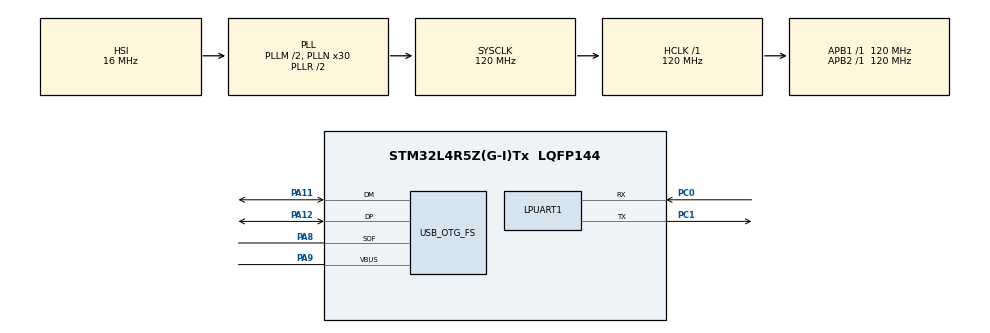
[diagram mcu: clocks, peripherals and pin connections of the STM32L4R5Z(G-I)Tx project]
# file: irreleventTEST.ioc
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LPUART1.WordLength=UART_WORDLENGTH_8B
Mcu.Family=STM32L4
Mcu.Name=STM32L4R5Z(G-I)Tx
Mcu.Package=LQFP144
NVIC.PriorityGroup=NVIC_PRIORITYGROUP_4
PA11.Mode=Device_Only
PA11.Signal=USB_OTG_FS_DM
PA12.Mode=Device_Only
PA12.Signal=USB_OTG_FS_DP
PA8.Mode=Activate_SOF_FS
PA8.Signal=USB_OTG_FS_SOF
PA9.Mode=Activate_VBUS
PA9.Signal=USB_OTG_FS_VBUS
PC0.Mode=Asynchronous
PC0.Signal=LPUART1_RX
PC1.Mode=Asynchronous
PC1.Signal=LPUART1_TX
ProjectManager.HeapSize=0x200
ProjectManager.StackSize=0x400
ProjectManager.TargetToolchain=STM32CubeIDE
RCC.ADCFreq_Value=96000000
RCC.AHBFreq_Value=120000000
RCC.APB1Freq_Value=120000000
RCC.APB1TimFreq_Value=120000000
RCC.APB2Freq_Value=120000000
RCC.APB2TimFreq_Value=120000000
RCC.CK48CLockSelection=RCC_USBCLKSOURCE_HSI48
RCC.CortexFreq_Value=120000000
RCC.HCLKFreq_Value=120000000
RCC.HSE_VALUE=8000000
RCC.HSI48_VALUE=48000000
RCC.HSI_VALUE=16000000
RCC.LSE_VALUE=32768
RCC.MSI_VALUE=4000000
RCC.PLLM1=2
RCC.PLLN=30
RCC.PLLSAI1N=12
RCC.PLLSourceVirtual=RCC_PLLSOURCE_HSI
RCC.SYSCLKFreq_VALUE=120000000
RCC.SYSCLKSource=RCC_SYSCLKSOURCE_PLLCLK
RCC.USBFreq_Value=48000000
RCC.VCOOutputFreq_Value=240000000
USB_OTG_FS.VirtualMode=Device_Only
board=custom

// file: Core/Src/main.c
/* USER CODE BEGIN Header */
/**
  ******************************************************************************
  * @file           : main.c
  * @brief          : Main program body
  ******************************************************************************
  * @attention
  *
  * Copyright (c) 2023 STMicroelectronics.
  * All rights reserved.
  *
  * This software is licensed under terms that can be found in the LICENSE file
  * in the root directory of this software component.
  * If no LICENSE file comes with this software, it is provided AS-IS.
  *
  ******************************************************************************
  */
/* USER CODE END Header */
#include "main.h"

UART_HandleTypeDef hlpuart1;

PCD_HandleTypeDef hpcd_USB_OTG_FS;

void SystemClock_Config(void);
static void MX_GPIO_Init(void);
static void MX_LPUART1_UART_Init(void);
static void MX_USB_OTG_FS_PCD_Init(void);

int main(void)
{

  /* MCU Configuration--------------------------------------------------------*/

  /* Reset of all peripherals, Initializes the Flash interface and the Systick. */
  HAL_Init();

  /* Configure the system clock */
  SystemClock_Config();

  /* Initialize all configured peripherals */
  MX_GPIO_Init();
  MX_LPUART1_UART_Init();
  MX_USB_OTG_FS_PCD_Init();
  /* USER CODE BEGIN 2 */
  char tt[50];
  char * msg = "start\n";
  HAL_UART_Transmit(&hlpuart1, (uint8_t*)msg, strlen(msg), HAL_MAX_DELAY);

  /* USER CODE END 2 */

  /* Infinite loop */
  /* USER CODE BEGIN WHILE */
  while (1)
  {

	  /**
	   * TEST PLAN:
	   * EMPTY CHAR ARRAY SIZE 50
	   * RECIEVE 1 CHAR
	   * USE TERMITE TO INPUT 10 CHAR
	   * TRANSMIT ARRAY
	   * SEE WHAT HAPPENS
	   */
	  HAL_UART_Receive(&hlpuart1, tt, 1, HAL_MAX_DELAY);
	  HAL_UART_Transmit(&hlpuart1, (uint8_t*)tt, strlen(tt), HAL_MAX_DELAY);

    /* USER CODE END WHILE */

  }
}

void SystemClock_Config(void)
{
  RCC_OscInitTypeDef RCC_OscInitStruct = {0};
  RCC_ClkInitTypeDef RCC_ClkInitStruct = {0};

  /** Configure the main internal regulator output voltage
  */
  if (HAL_PWREx_ControlVoltageScaling(PWR_REGULATOR_VOLTAGE_SCALE1_BOOST) != HAL_OK)
  {
    Error_Handler();
  }

  /** Initializes the RCC Oscillators according to the specified parameters
  * in the RCC_OscInitTypeDef structure.
  */
  RCC_OscInitStruct.OscillatorType = RCC_OSCILLATORTYPE_HSI48|RCC_OSCILLATORTYPE_HSI;
  RCC_OscInitStruct.HSIState = RCC_HSI_ON;
  RCC_OscInitStruct.HSI48State = RCC_HSI48_ON;
  RCC_OscInitStruct.HSICalibrationValue = RCC_HSICALIBRATION_DEFAULT;
  RCC_OscInitStruct.PLL.PLLState = RCC_PLL_ON;
  RCC_OscInitStruct.PLL.PLLSource = RCC_PLLSOURCE_HSI;
  RCC_OscInitStruct.PLL.PLLM = 2;
  RCC_OscInitStruct.PLL.PLLN = 30;
  RCC_OscInitStruct.PLL.PLLP = RCC_PLLP_DIV2;
  RCC_OscInitStruct.PLL.PLLQ = RCC_PLLQ_DIV2;
  RCC_OscInitStruct.PLL.PLLR = RCC_PLLR_DIV2;
  if (HAL_RCC_OscConfig(&RCC_OscInitStruct) != HAL_OK)
  {
    Error_Handler();
  }

  /** Initializes the CPU, AHB and APB buses clocks
  */
  RCC_ClkInitStruct.ClockType = RCC_CLOCKTYPE_HCLK|RCC_CLOCKTYPE_SYSCLK
                              |RCC_CLOCKTYPE_PCLK1|RCC_CLOCKTYPE_PCLK2;
  RCC_ClkInitStruct.SYSCLKSource = RCC_SYSCLKSOURCE_PLLCLK;
  RCC_ClkInitStruct.AHBCLKDivider = RCC_SYSCLK_DIV1;
  RCC_ClkInitStruct.APB1CLKDivider = RCC_HCLK_DIV1;
  RCC_ClkInitStruct.APB2CLKDivider = RCC_HCLK_DIV1;

  if (HAL_RCC_ClockConfig(&RCC_ClkInitStruct, FLASH_LATENCY_5) != HAL_OK)
  {
    Error_Handler();
  }
}

static void MX_LPUART1_UART_Init(void)
{

  hlpuart1.Instance = LPUART1;
  hlpuart1.Init.BaudRate = 209700;
  hlpuart1.Init.WordLength = UART_WORDLENGTH_8B;
  hlpuart1.Init.StopBits = UART_STOPBITS_1;
  hlpuart1.Init.Parity = UART_PARITY_NONE;
  hlpuart1.Init.Mode = UART_MODE_TX_RX;
  hlpuart1.Init.HwFlowCtl = UART_HWCONTROL_NONE;
  hlpuart1.Init.OneBitSampling = UART_ONE_BIT_SAMPLE_DISABLE;
  hlpuart1.Init.ClockPrescaler = UART_PRESCALER_DIV1;
  hlpuart1.AdvancedInit.AdvFeatureInit = UART_ADVFEATURE_NO_INIT;
  hlpuart1.FifoMode = UART_FIFOMODE_DISABLE;
  if (HAL_UART_Init(&hlpuart1) != HAL_OK)
  {
    Error_Handler();
  }
  if (HAL_UARTEx_SetTxFifoThreshold(&hlpuart1, UART_TXFIFO_THRESHOLD_1_8) != HAL_OK)
  {
    Error_Handler();
  }
  if (HAL_UARTEx_SetRxFifoThreshold(&hlpuart1, UART_RXFIFO_THRESHOLD_1_8) != HAL_OK)
  {
    Error_Handler();
  }
  if (HAL_UARTEx_DisableFifoMode(&hlpuart1) != HAL_OK)
  {
    Error_Handler();
  }

}

static void MX_USB_OTG_FS_PCD_Init(void)
{

  hpcd_USB_OTG_FS.Instance = USB_OTG_FS;
  hpcd_USB_OTG_FS.Init.dev_endpoints = 6;
  hpcd_USB_OTG_FS.Init.speed = PCD_SPEED_FULL;
  hpcd_USB_OTG_FS.Init.phy_itface = PCD_PHY_EMBEDDED;
  hpcd_USB_OTG_FS.Init.Sof_enable = ENABLE;
  hpcd_USB_OTG_FS.Init.low_power_enable = DISABLE;
  hpcd_USB_OTG_FS.Init.lpm_enable = DISABLE;
  hpcd_USB_OTG_FS.Init.battery_charging_enable = ENABLE;
  hpcd_USB_OTG_FS.Init.use_dedicated_ep1 = DISABLE;
  hpcd_USB_OTG_FS.Init.vbus_sensing_enable = ENABLE;
  if (HAL_PCD_Init(&hpcd_USB_OTG_FS) != HAL_OK)
  {
    Error_Handler();
  }

}

static void MX_GPIO_Init(void)
{

  /* GPIO Ports Clock Enable */
  __HAL_RCC_GPIOC_CLK_ENABLE();
  __HAL_RCC_GPIOA_CLK_ENABLE();

}

void Error_Handler(void)
{
  __disable_irq();
  while (1)
  {
  }
}
